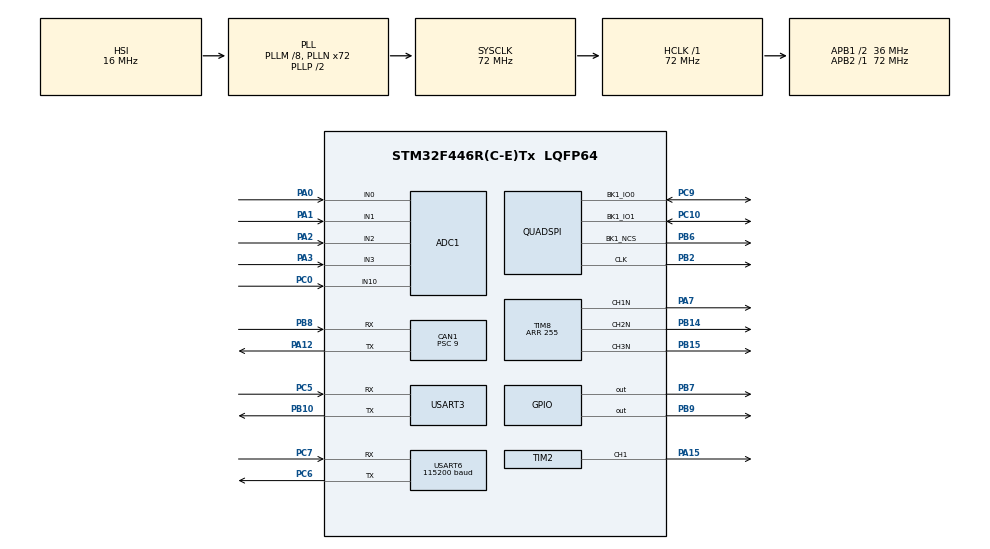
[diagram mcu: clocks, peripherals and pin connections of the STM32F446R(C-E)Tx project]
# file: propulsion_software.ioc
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ADC1.Channel-5\#ChannelRegularConversion=ADC_CHANNEL_2
ADC1.Channel-6\#ChannelRegularConversion=ADC_CHANNEL_10
ADC1.Channel-7\#ChannelRegularConversion=ADC_CHANNEL_0
ADC1.Channel-8\#ChannelRegularConversion=ADC_CHANNEL_1
ADC1.Channel-9\#ChannelRegularConversion=ADC_CHANNEL_3
ADC1.ContinuousConvMode=DISABLE
ADC1.DMAContinuousRequests=ENABLE
ADC1.EOCSelection=ADC_EOC_SEQ_CONV
ADC1.ExternalTrigConv=ADC_EXTERNALTRIGCONV_T3_CC1
ADC1.ExternalTrigConvEdge=ADC_EXTERNALTRIGCONVEDGE_RISINGFALLING
ADC1.NbrOfConversion=5
ADC1.NbrOfConversionFlag=1
ADC1.Rank-5\#ChannelRegularConversion=1
ADC1.Rank-6\#ChannelRegularConversion=2
ADC1.Rank-7\#ChannelRegularConversion=3
ADC1.Rank-8\#ChannelRegularConversion=4
ADC1.Rank-9\#ChannelRegularConversion=5
ADC1.SamplingTime-5\#ChannelRegularConversion=ADC_SAMPLETIME_15CYCLES
ADC1.SamplingTime-6\#ChannelRegularConversion=ADC_SAMPLETIME_15CYCLES
ADC1.SamplingTime-7\#ChannelRegularConversion=ADC_SAMPLETIME_15CYCLES
ADC1.SamplingTime-8\#ChannelRegularConversion=ADC_SAMPLETIME_15CYCLES
ADC1.SamplingTime-9\#ChannelRegularConversion=ADC_SAMPLETIME_15CYCLES
ADC1.master=1
CAN1.BS1=CAN_BS1_13TQ
CAN1.BS2=CAN_BS2_2TQ
CAN1.CalculateTimeQuantum=250.0
CAN1.Prescaler=9
Dma.ADC1.2.Direction=DMA_PERIPH_TO_MEMORY
Dma.ADC1.2.FIFOMode=DMA_FIFOMODE_DISABLE
Dma.ADC1.2.Instance=DMA2_Stream0
Dma.ADC1.2.MemDataAlignment=DMA_MDATAALIGN_HALFWORD
Dma.ADC1.2.MemInc=DMA_MINC_ENABLE
Dma.ADC1.2.Mode=DMA_CIRCULAR
Dma.ADC1.2.PeriphDataAlignment=DMA_PDATAALIGN_HALFWORD
Dma.ADC1.2.PeriphInc=DMA_PINC_DISABLE
Dma.ADC1.2.Priority=DMA_PRIORITY_HIGH
Dma.Request0=USART6_RX
Dma.Request1=USART3_RX
Dma.Request2=ADC1
Dma.USART3_RX.1.Direction=DMA_PERIPH_TO_MEMORY
Dma.USART3_RX.1.FIFOMode=DMA_FIFOMODE_DISABLE
Dma.USART3_RX.1.Instance=DMA1_Stream1
Dma.USART3_RX.1.MemDataAlignment=DMA_MDATAALIGN_BYTE
Dma.USART3_RX.1.MemInc=DMA_MINC_ENABLE
Dma.USART3_RX.1.Mode=DMA_CIRCULAR
Dma.USART3_RX.1.PeriphDataAlignment=DMA_PDATAALIGN_BYTE
Dma.USART3_RX.1.PeriphInc=DMA_PINC_DISABLE
Dma.USART3_RX.1.Priority=DMA_PRIORITY_LOW
Dma.USART6_RX.0.Direction=DMA_PERIPH_TO_MEMORY
Dma.USART6_RX.0.FIFOMode=DMA_FIFOMODE_DISABLE
Dma.USART6_RX.0.Instance=DMA2_Stream1
Dma.USART6_RX.0.MemDataAlignment=DMA_MDATAALIGN_BYTE
Dma.USART6_RX.0.MemInc=DMA_MINC_ENABLE
Dma.USART6_RX.0.Mode=DMA_CIRCULAR
Dma.USART6_RX.0.PeriphDataAlignment=DMA_PDATAALIGN_BYTE
Dma.USART6_RX.0.PeriphInc=DMA_PINC_DISABLE
Dma.USART6_RX.0.Priority=DMA_PRIORITY_LOW
FREERTOS.Tasks01=defaultTask,24,128,StartDefaultTask,Default,NULL,Dynamic,NULL,NULL
Mcu.Family=STM32F4
Mcu.Name=STM32F446R(C-E)Tx
Mcu.Package=LQFP64
NVIC.CAN1_RX0_IRQn=true\:5\:0\:true\:false\:true\:true\:true\:true
NVIC.DMA1_Stream1_IRQn=true\:5\:0\:true\:false\:true\:true\:false\:true
NVIC.DMA2_Stream0_IRQn=true\:5\:0\:true\:false\:true\:true\:false\:true
NVIC.DMA2_Stream1_IRQn=true\:5\:0\:true\:false\:true\:true\:false\:true
NVIC.PriorityGroup=NVIC_PRIORITYGROUP_4
NVIC.QUADSPI_IRQn=true\:5\:0\:true\:false\:true\:true\:true\:true
NVIC.TIM1_UP_TIM10_IRQn=true\:0\:0\:false\:false\:true\:false\:false\:true
NVIC.TimeBase=TIM1_UP_TIM10_IRQn
NVIC.TimeBaseIP=TIM1
PA0-WKUP.Signal=ADCx_IN0
PA1.Signal=ADCx_IN1
PA12.Mode=Master
PA12.Signal=CAN1_TX
PA15.Signal=S_TIM2_CH1_ETR
PA2.Signal=ADCx_IN2
PA3.Signal=ADCx_IN3
PA7.Mode=PWM Generation1 CH1N
PA7.Signal=TIM8_CH1N
PB10.Mode=Asynchronous
PB10.Signal=USART3_TX
PB14.Mode=PWM Generation2 CH2N
PB14.Signal=TIM8_CH2N
PB15.Mode=PWM Generation3 CH3N
PB15.Signal=TIM8_CH3N
PB2.Mode=Single Bank 1 2IOs
PB2.Signal=QUADSPI_CLK
PB6.Mode=Single Bank 1 2IOs
PB6.Signal=QUADSPI_BK1_NCS
PB7.Signal=GPIO_Output
PB8.Mode=Master
PB8.Signal=CAN1_RX
PB9.Signal=GPIO_Output
PC0.Signal=ADCx_IN10
PC10.Mode=Single Bank 1 2IOs
PC10.Signal=QUADSPI_BK1_IO1
PC5.Mode=Asynchronous
PC5.Signal=USART3_RX
PC6.GPIO_ModeDefaultPP=GPIO_MODE_AF_PP
PC6.GPIO_PuPd=GPIO_NOPULL
PC6.Mode=Asynchronous
PC6.Signal=USART6_TX
PC7.GPIO_ModeDefaultPP=GPIO_MODE_AF_PP
PC7.GPIO_PuPd=GPIO_NOPULL
PC7.Mode=Asynchronous
PC7.Signal=USART6_RX
PC9.Mode=Single Bank 1 2IOs
PC9.Signal=QUADSPI_BK1_IO0
ProjectManager.HeapSize=0x200
ProjectManager.StackSize=0x400
ProjectManager.TargetToolchain=STM32CubeIDE
QUADSPI.ClockPrescaler=50
QUADSPI.FlashSize=26
RCC.AHBFreq_Value=72000000
RCC.APB1CLKDivider=RCC_HCLK_DIV2
RCC.APB1Freq_Value=36000000
RCC.APB1TimFreq_Value=72000000
RCC.APB2Freq_Value=72000000
RCC.APB2TimFreq_Value=72000000
RCC.CortexFreq_Value=72000000
RCC.HCLKFreq_Value=72000000
RCC.PLLM=8
RCC.PLLN=72
RCC.PLLQ=3
RCC.SYSCLKFreq_VALUE=72000000
RCC.SYSCLKSource=RCC_SYSCLKSOURCE_PLLCLK
RCC.USBFreq_Value=48000000
RCC.VCOOutputFreq_Value=144000000
SH.ADCx_IN0.0=ADC1_IN0,IN0
SH.ADCx_IN1.0=ADC1_IN1,IN1
SH.ADCx_IN10.0=ADC1_IN10,IN10
SH.ADCx_IN2.0=ADC1_IN2,IN2
SH.ADCx_IN3.0=ADC1_IN3,IN3
SH.S_TIM2_CH1_ETR.0=TIM2_CH1,PWM Generation1 CH1
TIM2.AutoReloadPreload=TIM_AUTORELOAD_PRELOAD_DISABLE
TIM2.Channel-PWM\ Generation1\ CH1=TIM_CHANNEL_1
TIM2.CounterMode=TIM_COUNTERMODE_DOWN
TIM2.Period=1000
TIM2.Prescaler=49
TIM2.Pulse-PWM\ Generation1\ CH1=500
TIM2.TIM_MasterOutputTrigger=TIM_TRGO_RESET
TIM3.Channel-Output\ Compare1\ No\ Output=TIM_CHANNEL_1
TIM3.CounterMode=TIM_COUNTERMODE_UP
TIM3.OCMode_1=TIM_OCMODE_TOGGLE
TIM3.Period=1125
TIM3.Prescaler=0
TIM3.TIM_MasterOutputTrigger=TIM_TRGO_RESET
TIM8.Channel-PWM\ Generation1\ CH1N=TIM_CHANNEL_1
TIM8.Channel-PWM\ Generation2\ CH2N=TIM_CHANNEL_2
TIM8.Channel-PWM\ Generation3\ CH3N=TIM_CHANNEL_3
TIM8.OCNPolarity_1=TIM_OCNPOLARITY_LOW
TIM8.OCNPolarity_2=TIM_OCNPOLARITY_LOW
TIM8.OCNPolarity_3=TIM_OCNPOLARITY_LOW
TIM8.Period=255
USART3.VirtualMode=VM_ASYNC
USART6.BaudRate=115200
USART6.OverSampling=UART_OVERSAMPLING_16
USART6.VirtualMode=VM_ASYNC
VP_FREERTOS_VS_CMSIS_V2.Mode=CMSIS_V2
VP_SYS_VS_tim1.Mode=TIM1
VP_TIM2_VS_ClockSourceINT.Mode=Internal
VP_TIM3_VS_ClockSourceINT.Mode=Internal
VP_TIM3_VS_no_output1.Mode=Output Compare1 No Output
VP_TIM8_VS_ClockSourceINT.Mode=Internal
board=custom

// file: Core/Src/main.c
/* USER CODE BEGIN Header */
/**
  ******************************************************************************
  * @file           : main.c
  * @brief          : Main program body
  ******************************************************************************
  * @attention
  *
  * <h2><center>&copy; Copyright (c) 2020 STMicroelectronics.
  * All rights reserved.</center></h2>
  *
  * This software component is licensed by ST under BSD 3-Clause license,
  * the "License"; You may not use this file except in compliance with the
  * License. You may obtain a copy of the License at:
  *                        opensource.org/licenses/BSD-3-Clause
  *
  ******************************************************************************
  */
/* USER CODE END Header */
#include "main.h"
#include "cmsis_os.h"
#include "adc.h"
#include "can.h"
#include "dma.h"
#include "quadspi.h"
#include "tim.h"
#include "usart.h"
#include "gpio.h"

/* USER CODE BEGIN Includes */
#include <threads.h>

/* USER CODE END Includes */

void SystemClock_Config(void);
void MX_FREERTOS_Init(void);

int main(void)
{

  /* MCU Configuration--------------------------------------------------------*/

  /* Reset of all peripherals, Initializes the Flash interface and the Systick. */
  HAL_Init();

  /* Configure the system clock */
  SystemClock_Config();

  /* Initialize all configured peripherals */
  MX_GPIO_Init();
  MX_DMA_Init();
  MX_ADC1_Init();
  MX_TIM8_Init();
  MX_TIM2_Init();
  MX_USART6_UART_Init();
  MX_USART3_UART_Init();
  MX_CAN1_Init();
  MX_QUADSPI_Init();
  MX_TIM3_Init();
  /* USER CODE BEGIN 2 */
  HAL_TIMEx_PWMN_Start(&htim8,TIM_CHANNEL_1);
  HAL_TIMEx_PWMN_Start(&htim8,TIM_CHANNEL_2);
  HAL_TIMEx_PWMN_Start(&htim8,TIM_CHANNEL_3);

  /* USER CODE END 2 */

  /* Init scheduler */
  osKernelInitialize();  /* Call init function for freertos objects (in freertos.c) */
  MX_FREERTOS_Init();
  /* Start scheduler */
  osKernelStart();

  /* We should never get here as control is now taken by the scheduler */
  /* Infinite loop */
  while (1)
  {

	osDelay(1);
  }
}

void SystemClock_Config(void)
{
  RCC_OscInitTypeDef RCC_OscInitStruct = {0};
  RCC_ClkInitTypeDef RCC_ClkInitStruct = {0};

  /** Configure the main internal regulator output voltage
  */
  __HAL_RCC_PWR_CLK_ENABLE();
  __HAL_PWR_VOLTAGESCALING_CONFIG(PWR_REGULATOR_VOLTAGE_SCALE3);
  /** Initializes the RCC Oscillators according to the specified parameters
  * in the RCC_OscInitTypeDef structure.
  */
  RCC_OscInitStruct.OscillatorType = RCC_OSCILLATORTYPE_HSI;
  RCC_OscInitStruct.HSIState = RCC_HSI_ON;
  RCC_OscInitStruct.HSICalibrationValue = RCC_HSICALIBRATION_DEFAULT;
  RCC_OscInitStruct.PLL.PLLState = RCC_PLL_ON;
  RCC_OscInitStruct.PLL.PLLSource = RCC_PLLSOURCE_HSI;
  RCC_OscInitStruct.PLL.PLLM = 8;
  RCC_OscInitStruct.PLL.PLLN = 72;
  RCC_OscInitStruct.PLL.PLLP = RCC_PLLP_DIV2;
  RCC_OscInitStruct.PLL.PLLQ = 3;
  RCC_OscInitStruct.PLL.PLLR = 2;
  if (HAL_RCC_OscConfig(&RCC_OscInitStruct) != HAL_OK)
  {
    Error_Handler();
  }
  /** Initializes the CPU, AHB and APB buses clocks
  */
  RCC_ClkInitStruct.ClockType = RCC_CLOCKTYPE_HCLK|RCC_CLOCKTYPE_SYSCLK
                              |RCC_CLOCKTYPE_PCLK1|RCC_CLOCKTYPE_PCLK2;
  RCC_ClkInitStruct.SYSCLKSource = RCC_SYSCLKSOURCE_PLLCLK;
  RCC_ClkInitStruct.AHBCLKDivider = RCC_SYSCLK_DIV1;
  RCC_ClkInitStruct.APB1CLKDivider = RCC_HCLK_DIV2;
  RCC_ClkInitStruct.APB2CLKDivider = RCC_HCLK_DIV1;

  if (HAL_RCC_ClockConfig(&RCC_ClkInitStruct, FLASH_LATENCY_2) != HAL_OK)
  {
    Error_Handler();
  }
}

void HAL_TIM_PeriodElapsedCallback(TIM_HandleTypeDef *htim)
{
  if (htim->Instance == TIM1) {
    HAL_IncTick();
  }
}

void Error_Handler(void)
{
}

/************************ (C) COPYRIGHT STMicroelectronics *****END OF FILE****/

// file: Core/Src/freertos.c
/* USER CODE BEGIN Header */
/**
  ******************************************************************************
  * File Name          : freertos.c
  * Description        : Code for freertos applications
  ******************************************************************************
  * @attention
  *
  * <h2><center>&copy; Copyright (c) 2020 STMicroelectronics.
  * All rights reserved.</center></h2>
  *
  * This software component is licensed by ST under Ultimate Liberty license
  * SLA0044, the "License"; You may not use this file except in compliance with
  * the License. You may obtain a copy of the License at:
  *                             www.st.com/SLA0044
  *
  ******************************************************************************
  */
/* USER CODE END Header */

#include "FreeRTOS.h"
#include "task.h"
#include "main.h"
#include "cmsis_os.h"

/* USER CODE BEGIN Includes */
#include <threads.h>
/* USER CODE END Includes */

/* Definitions for defaultTask */
osThreadId_t defaultTaskHandle;
const osThreadAttr_t defaultTask_attributes = {
  .name = "defaultTask",
  .priority = (osPriority_t) osPriorityNormal,
  .stack_size = 128 * 4
};

void StartDefaultTask(void *argument);

void MX_FREERTOS_Init(void); /* (MISRA C 2004 rule 8.1) */

void MX_FREERTOS_Init(void) {

  /* Create the thread(s) */
  /* creation of defaultTask */
  defaultTaskHandle = osThreadNew(StartDefaultTask, NULL, &defaultTask_attributes);

  /* USER CODE BEGIN RTOS_THREADS */
  /* add threads, ... */
  PP_initThreads();
  /* USER CODE END RTOS_THREADS */

}

void StartDefaultTask(void *argument)
{
  for(;;)
  {
    osDelay(1);
  }
}

/************************ (C) COPYRIGHT STMicroelectronics *****END OF FILE****/
